# DA1470x register map
Vendor: Dialog; Series: DA1470x; File version: 1.2
CPU: CM33 r0p2, little endian, MPU, FPU, DSP, VTOR, 4 interrupt priority bits
Registers are 32-bit, read-write, reset 0x0 unless marked. A register's access mark holds for its fields unless they carry their own. Offsets are from the block's base; [hi:lo] are bit positions; <NAME> marks a mode.

## CHG_DET — CHG_DET registers
Base 0x50040300
0x00 CHG_DET_FSM_CTRL_REG — Charge detection FSM control register
  [0] CHG_DET_EN — 0 = Charge detection FSM is disabled, analog part is controlled through the USB_CHARGER_CTRL_REG register's bit-fields. 1 = Charge detection FSM is enabled and controls the analog part, overruling the content of USB_CHARGER_CTRL_REG.
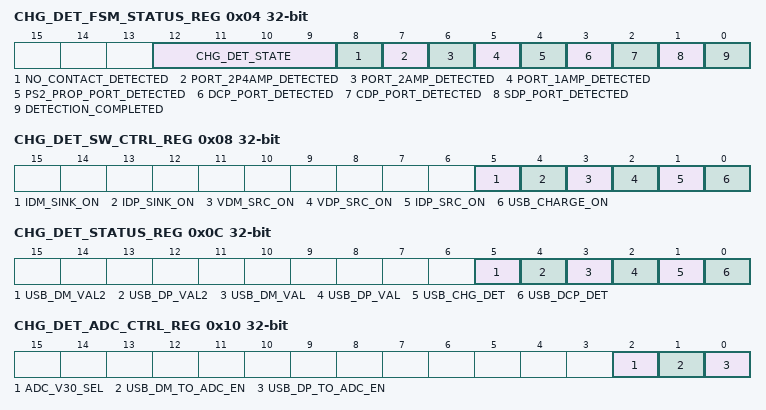
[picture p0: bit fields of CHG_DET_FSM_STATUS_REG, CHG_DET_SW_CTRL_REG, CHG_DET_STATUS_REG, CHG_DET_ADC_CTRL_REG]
0x04 CHG_DET_FSM_STATUS_REG — Charge detection FSM status register
  [12:9] CHG_DET_STATE ro — This bit-field returns the current state of the charge detection block's FSM. The supported states are: - 0x0 : WAIT_FOR_ATTACH (starting state) - 0x1 : NODE_ATTACHED (USB_DP_VAL first check) - 0x2 : WAIT_FOR_DCD (Data Contact Detection - first state) - 0x3 : CHECK_FOR_DCD (Data Contact Detection - second state) - 0x4 : WAIT_FOR_PCD (Primary Contact Detection - first state) - 0x5 : CHECK_FOR_PCD (Primary Contact Detection - second state) - 0x6 : WAIT_FOR_SCD (Secondary Contact Detection - first state) - 0x7 : CHECK_FOR_SCD (Secondary Contact Detection - second state) - 0x8 : CHG_PORT_DETECTED (terminal state, indicating the port detection's completion). It is noted that: - The FSM returns to state WAIT_FOR_ATTACH either when VBUS_AVAILABLE goes to '0', or when it is disabled by the SW. - The FSM may return to state WAIT_FOR_ATTACH from any of the other states when VBUS_AVAILABLE goes to '0', implying either a USB detach event or a VBUS voltage drop. - The FSM implements a time-out mechanism during the Data Contact Detection phase (NODE_ATTACHED, WAIT_FOR_DCD and CHECK_FOR_DCD states). A dedicated 10-bit timer counts down in any of these states, until USB_DP_VAL is found to be '0' (so we have a contact detected) or until it expires. - The time-out timer's expiration means that there is no D+/D- pins contact detected within the required time-out period, as defined through CHG_DET_DCD_TIMER_REG and as required by the spec. Even in this case though, the FSM does not abort, but proceeds normally to the next state, which is the first Primary Detection State, to comply with the Battery Charging specification.
  [8] NO_CONTACT_DETECTED ro — 0 = Contact is sensed on the Dp/Dm (data) pins by the FSM, during the Data Contact Detection (DCD) phase (USB_DP_VAL = 0) 1 = No contact is sensed on the Dp/Dm pins during the DCD phase (USB_DP_VAL = 1) Note: Even in the case of no contact detected on the Dp/Dm pins, the FSM continues with the port detection procedure, moving to the Primary Contact Detection (PCD) states.
  [7] PORT_2P4AMP_DETECTED ro — 0 = Port detection either not yet finished or finished without detecting a 2.4 Amp charging port 1 = Port detection has finished by detecting a 2.4 Amp charging port
  [6] PORT_2AMP_DETECTED ro — 0 = Port detection either not yet finished or finished without detecting a 2 Amp charging port 1 = Port detection has finished by detecting a 2 Amp charging port
  [5] PORT_1AMP_DETECTED ro — 0 = Port detection either not yet finished or finished without detecting a 1 Amp charging port 1 = Port detection has finished by detecting a 1 Amp charging port
  [4] PS2_PROP_PORT_DETECTED ro — 0 = Port detection either not yet finished or finished without detecting a PS2 or a Proprietary charger port 1 = Port detection has finished by detecting either a PS2 or a Proprietary charger port
  [3] DCP_PORT_DETECTED ro — 0 = Port detection either not yet finished or finished without detecting a DCP port (Dedicated Charging Port) 1 = Port detection has finished by detecting a DCP port
  [2] CDP_PORT_DETECTED ro — 0 = Port detection either not yet finished or finished without detecting a CDP port (Charging Downstream Port) 1 = Port detection has finished by detecting a CDP port
  [1] SDP_PORT_DETECTED ro — 0 = Port detection either not yet finished or finished without detecting an SDP port (Standard Downstream Port) 1 = Port detection has finished by detecting an SDP port
  [0] DETECTION_COMPLETED ro — 0 = Port detection not yet finished, FSM still active 1 = Port detection completed, FSM has reached its terminal state (CHG_PORT_DETECTED). The port type is accessible through the relevant bit-fields of this register.
0x08 CHG_DET_SW_CTRL_REG — Charge detection manual (SW-based) mode control register
  [5] IDM_SINK_ON — 0 = Disables the Idm_sink to USBm 1 = Enables the Idm_sink to USBm
  [4] IDP_SINK_ON — 0 = Disables the Idp_sink to USBp 1 = Enables the Idp_sink to USBp
  [3] VDM_SRC_ON — 0 = Disables the Vdm_src 1 = Enables the Vdm to USBm and also the USB_DCP_DET status bit
  [2] VDP_SRC_ON — 0 = Disables the Vdp_src 1 = Enables the Vdp_src and also the USB_CHG_DET status bit
  [1] IDP_SRC_ON — 0 = Disables the Idp_src and the Rdm_dwn 1 = Enables the Idp_src and the Rdm_dwn
  [0] USB_CHARGE_ON — 0 = Disables the charge detection analog circuit 1 = Enables the charge detection analog circuit
0x0C CHG_DET_STATUS_REG — Charge detection status register holding the comparator outputs
  [5] USB_DM_VAL2 ro — 0: USBp < 2.3V 1: USBp > 2.5V
  [4] USB_DP_VAL2 ro — 0: USBp < 2.3V 1: USBp > 2.5V
  [3] USB_DM_VAL ro — 0 = USBm < 0.8V 1 = USBm > 1.5V (PS2 or Proprietary Charger)
  [2] USB_DP_VAL ro — 0 = USBp < 0.8V 1 = USBp > 1.5V (PS2 or Proprietary Charger)
  [1] USB_CHG_DET ro — 0 = Standard Downstream Port (SDP) or no Dp/Dm contact detected (nothing connected) 1 = Charging Downstream Port (CDP) or Dedicated Charging Port (DCP)
  [0] USB_DCP_DET ro — 0 = Charging downstream port is detected 1 = Dedicated charger is detected It is noted that the control bit VDM_SRC_ON must be set to validate this status bit. Note: This register shows the actual status.
0x10 CHG_DET_ADC_CTRL_REG — Charge detection ADC control register
  [2] ADC_V30_SEL — This bit-field determines the mode to be used when the intention is to measure the USB Dp/Dm levels with the GP_ADC. In specific: 0 = Should be used when the V30 rail is at 3.0V 1 = Should be used when the V30 rail is at 3.3V
  [1] USB_DM_TO_ADC_EN — 0 = Disables the connection of USBm to the GP_ADC 1 = Enables the connection of USBm to the GP_ADC through a relative test switch
  [0] USB_DP_TO_ADC_EN — 0 = Disables the connection of USBp to the GP_ADC 1 = Enables the connection of USBp to the GP_ADC through a relative test switch
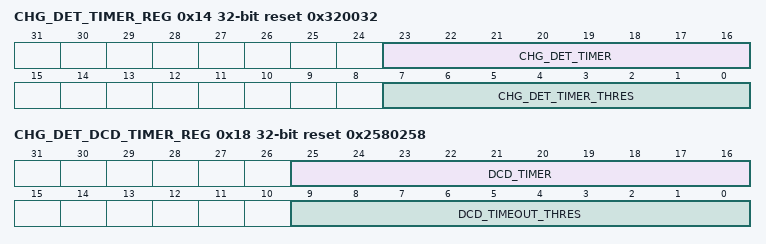
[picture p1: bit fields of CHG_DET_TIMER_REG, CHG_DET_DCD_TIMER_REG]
0x14 CHG_DET_TIMER_REG reset 0x320032 — Charge detection timer register (used in the FSM)
  [23:16] CHG_DET_TIMER ro — This bit-field returns the current value of the charge detection timer, which is used by the FSM and which down-counts with a clock of 1KHz. The specific clock is enabled by setting the CLK_SYS_REG[CLK_CHG_EN] bit-field to '1' and it is the same clock used by the Charger's digital block. The specific timer is automatically re-loaded with the programmed threshold value (CHG_DET_TIMER_THRES), upon expiring to zero or when the charge detection FSM moves to the state NODE_ATTACHED (0x1).
  [7:0] CHG_DET_TIMER_THRES — This bit-field determines the value from which the charge detection timer starts down-counting, until expiring to zero. Non-zero values are recommended.
0x18 CHG_DET_DCD_TIMER_REG reset 0x2580258 — Charge detection DCD time-out timer register (used in the FSM)
  [25:16] DCD_TIMER ro — This bit-field returns the current value of the DCD time-out timer, also ticking with the 1KHz clock, same as the shared 8-bit timer. The specific timer counts only in states NODE_ATTACHED, WAIT_FOR_DCD and CHECK_FOR_DCD, since these are the states where Data Contact Detection is evaluated. The timer is automatically reloaded with the programmed threshold value (DCD_TIMEOUT_THRES) as soon as the FSM returns to its starting state (WAIT_FOR_ATTACH, 0x0).
  [9:0] DCD_TIMEOUT_THRES — This bit-field determines the value from which the Data Contact Detection (DCD) time-out timer starts down-counting, until expiring to zero. Non-zero values are recommended.
0x1C CHG_DET_IRQ_MASK_REG — Charge detection IRQ mask register
  [0] CHG_DET_IRQ_EN — 0 = Charge detection block's IRQ generation is disabled, interrupts to Cortex-M33 are masked. 1 = Charge detection block's IRQ generation is enabled.
0x20 CHG_DET_IRQ_STATUS_REG — Charge detection IRQ status register
  [0] CHG_DET_IRQ ro — 0 = No new charge detection IRQ has been generated. 1 = A new charge detection IRQ is generated and should be cleared by SW, by writing to CHG_DET_IRQ_CLEAR_REG (interrupt is level-sensitive).
0x24 CHG_DET_IRQ_CLEAR_REG — Charge detection IRQ clear register
  [0] CHG_DET_IRQ_CLR wo — Writing any value to this register clears the charge detection IRQ, reading always returns zero.
